# CC27x0 register map
File version: 1.0
CPU: CM4 r0p4, little endian, no MPU, no FPU, VTOR, 3 interrupt priority bits
Registers are 32-bit, read-write, reset 0x0 unless marked. A register's access mark holds for its fields unless they carry their own. Offsets are from the block's base; [hi:lo] are bit positions; {n}, {i} and the like mark numbered series; 'fields as' and 'values as' point back to an identical list.

## LRFDDBELL
Base 0x40080000
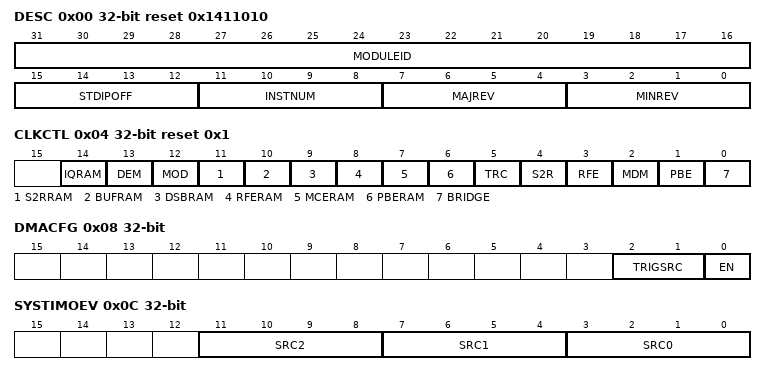
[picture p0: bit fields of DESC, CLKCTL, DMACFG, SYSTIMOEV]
0x00 DESC ro reset 0x1411010 — Description. This register identifies the peripheral and its exact version.
  [31:16] MODULEID — Module identifier used to uniquely identify this IP.
  [15:12] STDIPOFF — Standard IP MMR block offset. Standard IP MMRs are the set of from aggregated IRQ registers till DTB.
    1=STDIPMMR (These MMRs begin at offset 64*STDIPOFF from IP base address); 0=NO_STDIPMMR (STDIP MMRs do not exist)
  [11:8] INSTNUM — IP Instance Number. If multiple instances of IP exist in the device, this field can identify the instance number
  [7:4] MAJREV — Major rev of the IP
  [3:0] MINREV — Minor rev of the IP
0x04 CLKCTL reset 0x1 — Systimer Output Event Control Register. Controls the functional clock gates for the individual sub-modules.
  [14] IQRAM — Enable the clock to the demodulator
    1=EN (The bit is 1); 0=DIS (The bit is 0)
  [13] DEM — Enable the clock to the demodulator. The modem will request this clock automatically. This bit is to force the clock to be free running
    1=EN (Clock is requested); 0=DIS (Clock not requested)
  [12] MOD — Enable the clock to the modulator. Modem will request this clock automatically, this bit is to force the modulator clock to be free running.
    1=EN (Clock is requested); 0=DIS (Clock not requested)
  [11] S2RRAM — Enable the clock to the S2R RAM
    1=EN (The bit is 1); 0=DIS (Clock not requested)
  [10] BUFRAM — Enable the clock to the BUFRAM
    1=EN (Clock is requested); 0=DIS (Clock not requested)
  [9] DSBRAM — Enable the clock to the DSB RAM
    1=EN (Clock is requested); 0=DIS (Clock not requested)
  [8] RFERAM — Enable the clock to the RFE RAM
    1=EN (Clock is requested); 0=DIS (Clock not requested)
  [7] MCERAM — Enable the clock to the MCE RAM
    1=EN (Clock is requested); 0=DIS (Clock not requested)
  [6] PBERAM — Enable the clock to the PBE RAM
    1=EN (Clock is requested); 0=DIS (Clock not requested)
  [5] TRC — Enable the clock to the Tracer
    1=EN (Clock is requested); 0=DIS (Clock not requested)
  [4] S2R — Enable the clock to Samples2RAM
    1=EN (Clock is requested); 0=DIS (Clock not requested)
  [3] RFE — Enable the clock to the RFE
    1=EN (Clock is requested); 0=DIS (Clock not requested)
  [2] MDM — Enable the clock to the Modem
    1=EN (Clock is requested); 0=DIS (Clock not requested)
  [1] PBE — Enable the clock to the PBE
    1=EN (Clock is requested); 0=DIS (Clock not requested)
  [0] BRIDGE — Clock enable to AHB bridge. The bridge will request it's own clock, this bit it to override that feature to have a free running clock.
    1=EN (Clock is requested); 0=DIS (Clock not requested)
0x08 DMACFG — DMA Configuration
  [2:1] TRIGSRC — Select DMA trigger source
    3=FIFO (The DMA is triggered from the FIFO. See the FIFO configration register for what FIFO event will generate the trigger); 2=RFEFW (The DMA is triggered by the MCE FW trigger); 1=MCEFW (The DMA is triggered by the MCE FW trigger); 0=PBEFW (The DMA is triggered by the PBE FW trigger)
  [0] EN — Enables the DMA interface
    1=ON (Enable DMA interface. The triggers are able to give activity on the interface); 0=OFF (Disable DMA interface, no activity on interface)
0x0C SYSTIMOEV — Systimer Output Event Control Register. Controls routing of internal events to the three systimer output events
  [all] fields
    12=PBESYSTIM2 (PBE FW systimer capture event 2); 11=PBESYSTIM1 (PBE FW systimer capture event 1); 10=PBESYSTIM0 (PBE FW systimer capture event 0); 9=MDMHW2 (MDM HW event 2); 8=MDMHW1 (MDM HW event 1); 7=MDMHW0 (MDM HW event 0); 6=MCESYSTIM2 (MCE FW systimer capture event 2); 5=MCESYSTIM1 (MCE FW systimer capture event 1); 4=MCESYSTIM0 (MCE FW systimer capture event 0); 3=RFESYSTIM2 (RFE FW systimer capture event 2); 2=RFESYSTIM1 (RFE FW systimer capture event 1); 1=RFESYSTIM0 (RFE FW systimer capture event 0); 0=DIS (Output not enabled, always 0.)
  [11:8] SRC2 — Select source of systimer output event 2 (capture source)
  [7:4] SRC1 — Select source of systimer output event 1 (capture source)
  [3:0] SRC0 — Select source of systimer output event 0 (capture source)
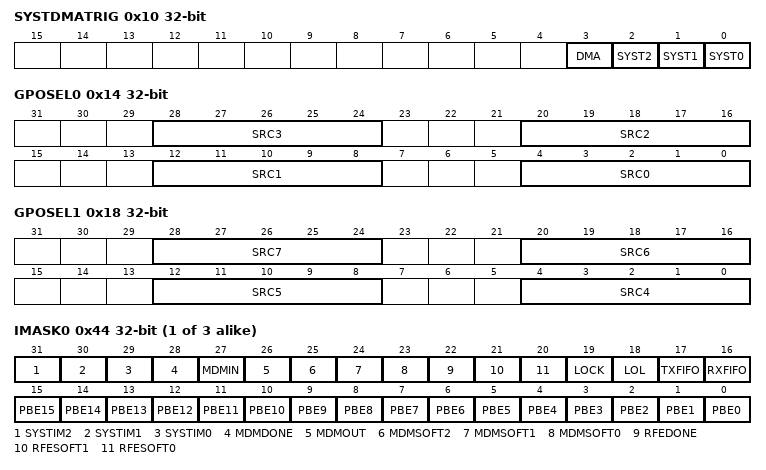
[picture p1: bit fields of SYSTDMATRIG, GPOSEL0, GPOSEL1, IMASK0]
0x10 SYSTDMATRIG wo — System DMA Trigger. Manual triggering of systimer capture event or DMA trigger This comes on top of any HW driven sources configured in SYSTIMOEV
  [3] DMA — Trigger a DMA request from the Radio
    1=TRIG (DMA request manually triggered); 0=NOTRIG (DMA not manually triggered)
  [2] SYST2 — Trigger a capture event on systimer event 0 from the radio
    1=TRIG (Capture event triggered); 0=NOTRIG (Not capture event triggered)
  [1] SYST1 — Trigger a capture event on systimer event 0 from the radio
    values as SYST2
  [0] SYST0 — Trigger a capture event on systimer event 0 from the radio
    values as SYST2
0x14 GPOSEL0 — Controls routing of GPO signals from MDM, RFE and PBE to the radio GPO lines
  [8n+4:8n] SRC{n} (n=0..3) — Select source of radio GPO line {n}
    25=RFCTRC (Select RFCTRC GPO line {n}); {v}=RFEGPO{v-17} (Select RFE GPO line {v-17}) (v=17..24); {v}=MCEGPO{v-9} (Select MCE GPO line {v-9}) (v=9..16); {v}=PBEGPO{v-1} (Select PBE GPO line {v-1}) (v=1..8); 0=DIS (Output not enabled)
0x18 GPOSEL1 — Controls routing of GPO signals from MDM, RFE and PBE to the radio GPO lines
  [28:24] SRC7 — Select source of radio GPO line 7
    25=RFCTRC (Select RFCTRC GPO line 7); {v}=RFEGPO{v-17} (Select RFE GPO line {v-17}) (v=17..24); {v}=MCEGPO{v-9} (Select MCE GPO line {v-9}) (v=9..16); {v}=PBEGPO{v-1} (Select PBE GPO line {v-1}) (v=1..8); 0=DIS (No output not enabled)
  [20:16] SRC6 — Select source of radio GPO line 6
    25=RFCTRC (Select RFCTRC GPO line 6); {v}=RFEGPO{v-17} (Select RFE GPO line {v-17}) (v=20..24); 19=RFEGPO2 (Selevt RFE GPO line 2); 18=RFEGPO1 (Select RFE GPO line 1); 17=RFEGPO0 (Select RFE GPO line 0); {v}=MCEGPO{v-9} (Select MCE GPO line {v-9}) (v=9..16); {v}=PBEGPO{v-1} (Select PBE GPO line {v-1}) (v=1..8); 0=DIS (No output not enabled)
  [12:8] SRC5 — Select source of radio GPO line 5
    25=RFCTRC (Select RFCTRC GPO line 5); {v}=RFEGPO{v-17} (Select RFE GPO line {v-17}) (v=17..24); {v}=MCEGPO{v-9} (Select MCE GPO line {v-9}) (v=9..16); {v}=PBEGPO{v-1} (Select PBE GPO line {v-1}) (v=1..8); 0=DIS (No output not enabled)
  [4:0] SRC4 — Select source of radio GPO line 4
    25=RFCTRC (Select RFCTRC GPO line 4); {v}=RFEGPO{v-17} (Select RFE GPO line {v-17}) (v=17..24); {v}=MCEGPO{v-9} (Select MCE GPO line {v-9}) (v=9..16); {v}=PBEGPO{v-1} (Select PBE GPO line {v-1}) (v=1..8); 0=DIS (No output not enabled)
{0x44+0x40*i} IMASK{i} (i=0..2) — Interrupt mask. This register selects interrupt sources which are allowed to pass from RIS to MIS when the corresponding bit-fields are set to 1.
  [all] fields
    1=EN (Enable interrupt mask); 0=DIS (Disable interrupt mask)
  [31] SYSTIM2 — SYSTIM2 event
  [30] SYSTIM1 — SYSTIM1 event
  [29] SYSTIM0 — SYSTIM0 event
  [28] MDMDONE — MDMDONE event
  [27] MDMIN — MDMIN event
  [26] MDMOUT — MDMOUT event
  [25] MDMSOFT2 — MDMSOFT2 event
  [24] MDMSOFT1 — MDMSOFT1 event
  [23] MDMSOFT0 — MDMSOFT0 event
  [22] RFEDONE — RFEDONE event
  [21] RFESOFT1 — RFESOFT1 event
  [20] RFESOFT0 — RFESOFT0 event
  [19] LOCK — LOCK event
  [18] LOL — LOSS_OF_LOCK event
  [17] TXFIFO — TXFIFO event
  [16] RXFIFO — RXFIFO event
  [n] PBE{n} (n=0..15) — PBE{n} event
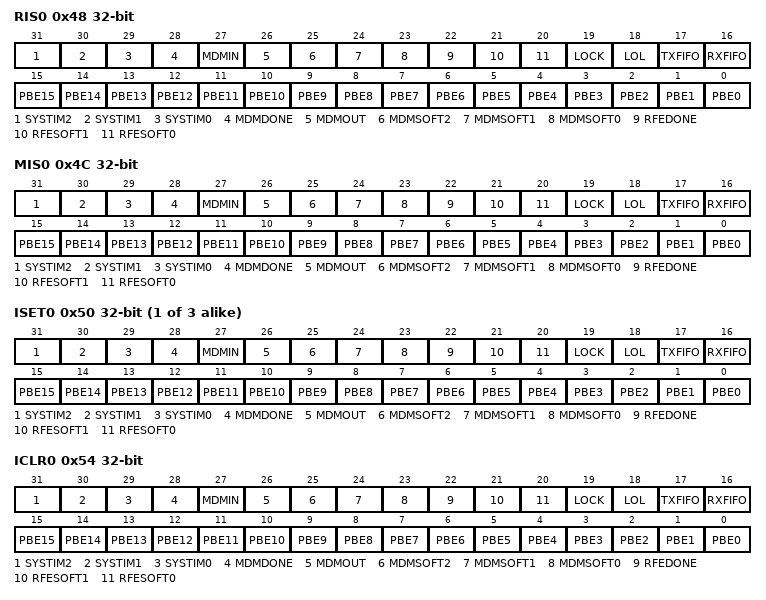
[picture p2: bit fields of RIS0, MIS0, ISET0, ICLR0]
0x48 RIS0 ro — Raw interrupt status. This register reflects the state of all pending interrupts, regardless of masking. This register allows the user to implement a poll scheme. A flag set in this register can be cleared by writing 1 to the corresponding ICLR register bit.
  [all] fields
    1=SET (Interrupt occurred); 0=CLR (Interrupt did not occur)
  [31] SYSTIM2 — SYSTIM2 event
  [30] SYSTIM1 — SYSTIM1 event
  [29] SYSTIM0 — SYSTIM0 event
  [28] MDMDONE — MDMDONE event
  [27] MDMIN — MDMIN event
  [26] MDMOUT — MDMOUT event
  [25] MDMSOFT2 — MDMSOFT2 event
  [24] MDMSOFT1 — MDMSOFT1 event
  [23] MDMSOFT0 — MDMSOFT0 event
  [22] RFEDONE — RFEDONE event
  [21] RFESOFT1 — RFESOFT1 event
  [20] RFESOFT0 — RFESOFT0 event
  [19] LOCK — LOCK event
  [18] LOL — LOSS_OF_LOCK event
  [17] TXFIFO — TXFIFO event
  [16] RXFIFO — RXFIFO event
  [n] PBE{n} (n=0..15) — PBE{n} event
0x4C MIS0 ro — Masked interrupt status. This register is simply a bitwise AND of the contents of IMASK and RIS.*] registers. A flag set in this register can be cleared by writing 1 to the corresponding ICLR register bit.
  fields as RIS0
{0x50+0x40*i} ISET{i} wo (i=0..2) — Interrupt set register. This register can used by software for diagnostics and safety checking purposes. Writing a 1 to a bit in this register will set the event and the corresponding RIS bit also gets set. If the corresponding IMASK bit is set, then the corresponding MIS register bit also gets set.
  [all] fields
    1=SET (Set Interrupt); 0=NOEFF (Writing 0 has no effect)
  [31] SYSTIM2 — SYSTIM2 event
  [30] SYSTIM1 — SYSTIM1 event
  [29] SYSTIM0 — SYSTIM0 event
  [28] MDMDONE — MDMDONE event
  [27] MDMIN — MDMIN event
  [26] MDMOUT — MDMOUT event
  [25] MDMSOFT2 — MDMSOFT2 event
  [24] MDMSOFT1 — MDMSOFT1 event
  [23] MDMSOFT0 — MDMSOFT0 event
  [22] RFEDONE — RFEDONE event
  [21] RFESOFT1 — RFESOFT1 event
  [20] RFESOFT0 — RFESOFT0 event
  [19] LOCK — LOCK event
  [18] LOL — LOSS_OF_LOCK event
  [17] TXFIFO — TXFIFO event
  [16] RXFIFO — RXFIFO event
  [n] PBE{n} (n=0..15) — PBE{n} event
0x54 ICLR0 wo — Interrupt clear. Write a 1 to clear corresponding Interrupt.
  [all] fields
    1=CLR (Clear Interrupt); 0=NOEFF (Writing 0 has no effect)
  [31] SYSTIM2 — SYSTIM2 event
  [30] SYSTIM1 — SYSTIM1 event
  [29] SYSTIM0 — SYSTIM0 event
  [28] MDMDONE — MDMDONE event
  [27] MDMIN — MDMIN event
  [26] MDMOUT — MDMOUT event
  [25] MDMSOFT2 — MDMSOFT2 event
  [24] MDMSOFT1 — MDMSOFT1 event
  [23] MDMSOFT0 — MDMSOFT0 event
  [22] RFEDONE — RFEDONE event
  [21] RFESOFT1 — RFESOFT1 event
  [20] RFESOFT0 — RFESOFT0 event
  [19] LOCK — LOCK event
  [18] LOL — LOSS_OF_LOCK event
  [17] TXFIFO — TXFIFO event
  [16] RXFIFO — RXFIFO event
  [n] PBE{n} (n=0..15) — PBE{n} event
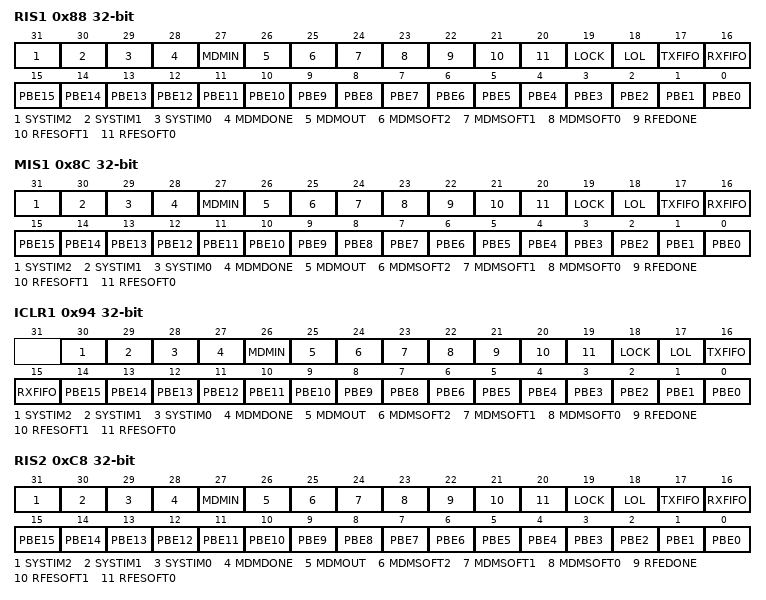
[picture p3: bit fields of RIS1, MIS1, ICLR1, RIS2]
0x88 RIS1 — Raw interrupt status. Reflects all pending interrupts, regardless of masking. The RIS0 register allows the user to implement a poll scheme. A flag set in this register can be cleared by writing 1 to the ICLR register bit even if the corresponding IMASK bit is not enabled.
  [all] fields
    1=SET (Interrupt occurred); 0=CLR (Interrupt did not occur)
  [31] SYSTIM2 ro — SYSTIM2 event
  [30] SYSTIM1 ro — SYSTIM1 event
  [29] SYSTIM0 ro — SYSTIM0 event
  [28] MDMDONE ro — MDMDONE event
  [27] MDMIN ro — MDMIN event
  [26] MDMOUT ro — MDMOUT event
  [25] MDMSOFT2 ro — MDMSOFT2 event
  [24] MDMSOFT1 ro — MDMSOFT1 event
  [23] MDMSOFT0 ro — MDMSOFT0 event
  [22] RFEDONE ro — RFEDONE event
  [21] RFESOFT1 ro — RFESOFT1 event
  [20] RFESOFT0 ro — RFESOFT0 event
  [19] LOCK ro — LOCK event
  [18] LOL ro — LOSS_OF_LOCK event
  [17] TXFIFO ro — TXFIFO event
  [16] RXFIFO ro — RXFIFO event
  [n] PBE{n} ro (n=0..15) — PBE{n} event
0x8C MIS1 ro — Masked interrupt status. This is an AND of the IMASK and RIS registers.
  fields as RIS0
0x94 ICLR1 wo — Interrupt clear. Write a 1 to clear corresponding Interrupt.
  [all] fields
    1=CLR (Clear Interrupt); 0=NOEFF (Writing 0 has no effect)
  [30] SYSTIM2 — SYSTIM2 event
  [29] SYSTIM1 — SYSTIM1 event
  [28] SYSTIM0 — SYSTIM0 event
  [27] MDMDONE — MDMDONE event
  [26] MDMIN — MDMIN event
  [25] MDMOUT — MDMOUT event
  [24] MDMSOFT2 — MDMSOFT2 event
  [23] MDMSOFT1 — MDMSOFT1 event
  [22] MDMSOFT0 — MDMSOFT0 event
  [21] RFEDONE — RFEDONE event
  [20] RFESOFT1 — RFESOFT1 event
  [19] RFESOFT0 — RFESOFT0 event
  [18] LOCK — LOCK event
  [17] LOL — LOSS_OF_LOCK event
  [16] TXFIFO — TXFIFO event
  [15] RXFIFO — RXFIFO event
  [n-1] PBE{n} (n=8..15) — PBE{n} event
  [n] PBE{n} (n=0..6) — PBE{n} event
0xC8 RIS2 — Raw interrupt status. Reflects all pending interrupts, regardless of masking. The RIS0 register allows the user to implement a poll scheme. A flag set in this register can be cleared by writing 1 to the ICLR register bit even if the corresponding IMASK bit is not enabled.
  fields as RIS1
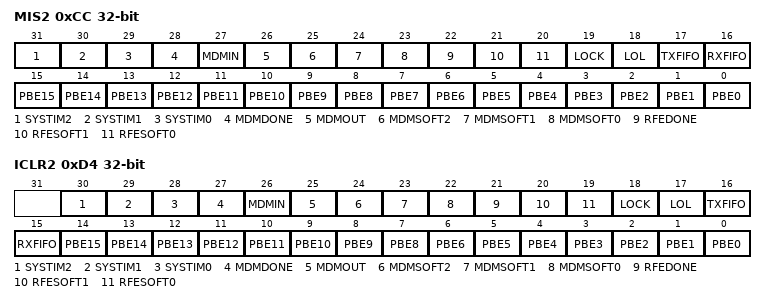
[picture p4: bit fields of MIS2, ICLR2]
0xCC MIS2 ro — Masked interrupt status. This is an AND of the IMASK and RIS registers.
  fields as RIS0
0xD4 ICLR2 wo — Interrupt clear. Write a 1 to clear corresponding Interrupt.
  fields as ICLR1
